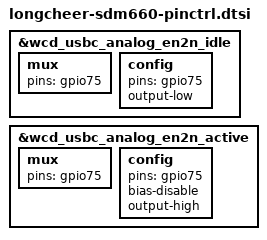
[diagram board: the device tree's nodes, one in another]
// SPDX-License-Identifier: GPL-2.0-only

#include "longcheer-sdm636-pinctrl.dtsi"

&wcd_usbc_analog_en2n_idle {
	mux {
		pins = "gpio75";
	};

	config {
		/delete-property/ output-high;
		pins = "gpio75";
		output-low;
	};
};

&wcd_usbc_analog_en2n_active {
	mux {
		pins = "gpio75";
	};

	config {
		/delete-property/ bias-pull-down;
		/delete-property/ output-low;
		pins = "gpio75";
		bias-disable;
		output-high;
	};
};
